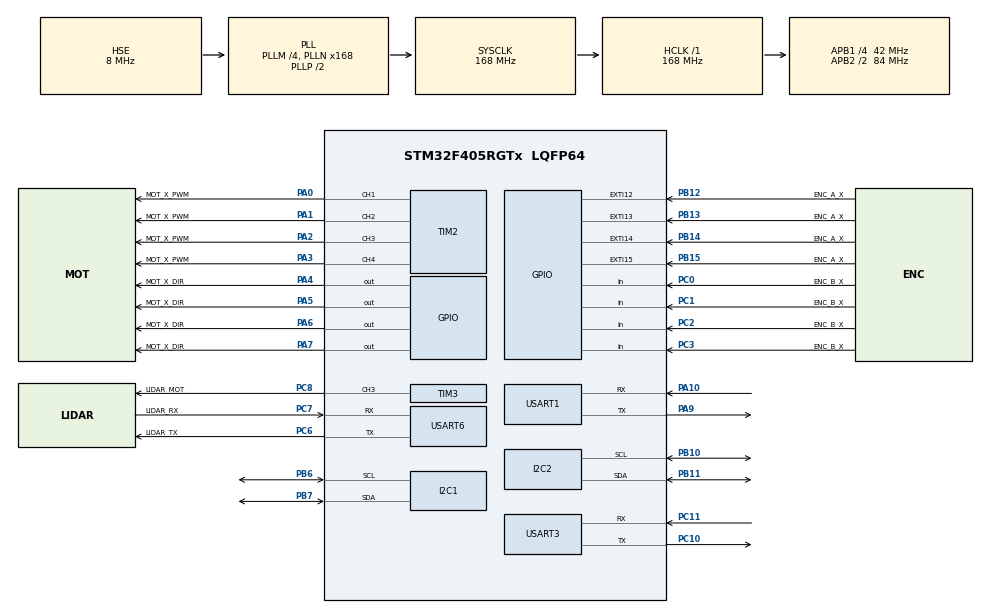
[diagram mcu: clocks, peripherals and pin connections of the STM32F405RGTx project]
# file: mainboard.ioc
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ADC1.Channel-2\#ChannelRegularConversion=ADC_CHANNEL_VBAT
ADC1.NbrOfConversion=1
ADC1.NbrOfConversionFlag=1
ADC1.Rank-2\#ChannelRegularConversion=1
ADC1.SamplingTime-2\#ChannelRegularConversion=ADC_SAMPLETIME_3CYCLES
ADC1.master=1
I2C1.I2C_Mode=I2C_Fast
I2C2.I2C_Mode=I2C_Fast
Mcu.Family=STM32F4
Mcu.Name=STM32F405RGTx
Mcu.Package=LQFP64
NVIC.EXTI15_10_IRQn=true\:0\:0\:false\:false\:true\:true\:true\:true
NVIC.PriorityGroup=NVIC_PRIORITYGROUP_4
PA0-WKUP.GPIO_Label=MOT_X_PWM
PA0-WKUP.Signal=S_TIM2_CH1_ETR
PA1.GPIO_Label=MOT_X_PWM
PA1.Signal=S_TIM2_CH2
PA10.Mode=Asynchronous
PA10.Signal=USART1_RX
PA13.Mode=Trace_Asynchronous_SW
PA13.Signal=SYS_JTMS-SWDIO
PA14.Mode=Trace_Asynchronous_SW
PA14.Signal=SYS_JTCK-SWCLK
PA2.GPIO_Label=MOT_X_PWM
PA2.Signal=S_TIM2_CH3
PA3.GPIO_Label=MOT_X_PWM
PA3.Signal=S_TIM2_CH4
PA4.GPIO_Label=MOT_X_DIR
PA4.Signal=GPIO_Output
PA5.GPIO_Label=MOT_X_DIR
PA5.Signal=GPIO_Output
PA6.GPIO_Label=MOT_X_DIR
PA6.Signal=GPIO_Output
PA7.GPIO_Label=MOT_X_DIR
PA7.Signal=GPIO_Output
PA9.Mode=Asynchronous
PA9.Signal=USART1_TX
PB10.Mode=I2C
PB10.Signal=I2C2_SCL
PB11.Mode=I2C
PB11.Signal=I2C2_SDA
PB12.GPIO_Label=ENC_A_X
PB12.Signal=GPXTI12
PB13.GPIO_Label=ENC_A_X
PB13.Signal=GPXTI13
PB14.GPIO_Label=ENC_A_X
PB14.Signal=GPXTI14
PB15.GPIO_Label=ENC_A_X
PB15.Signal=GPXTI15
PB3.Mode=Trace_Asynchronous_SW
PB3.Signal=SYS_JTDO-SWO
PB6.Mode=I2C
PB6.Signal=I2C1_SCL
PB7.Mode=I2C
PB7.Signal=I2C1_SDA
PC0.GPIO_Label=ENC_B_X
PC0.Signal=GPIO_Input
PC1.GPIO_Label=ENC_B_X
PC1.Signal=GPIO_Input
PC10.Mode=Asynchronous
PC10.Signal=USART3_TX
PC11.Mode=Asynchronous
PC11.Signal=USART3_RX
PC14-OSC32_IN.Mode=LSE-External-Oscillator
PC14-OSC32_IN.Signal=RCC_OSC32_IN
PC15-OSC32_OUT.Mode=LSE-External-Oscillator
PC15-OSC32_OUT.Signal=RCC_OSC32_OUT
PC2.GPIO_Label=ENC_B_X
PC2.Signal=GPIO_Input
PC3.GPIO_Label=ENC_B_X
PC3.Signal=GPIO_Input
PC6.GPIO_Label=LIDAR_TX
PC6.Mode=Asynchronous
PC6.Signal=USART6_TX
PC7.GPIO_Label=LIDAR_RX
PC7.Mode=Asynchronous
PC7.Signal=USART6_RX
PC8.GPIO_Label=LIDAR_MOT
PC8.Signal=S_TIM3_CH3
PH0-OSC_IN.Mode=HSE-External-Oscillator
PH0-OSC_IN.Signal=RCC_OSC_IN
PH1-OSC_OUT.Mode=HSE-External-Oscillator
PH1-OSC_OUT.Signal=RCC_OSC_OUT
ProjectManager.HeapSize=0x200
ProjectManager.StackSize=0x400
ProjectManager.TargetToolchain=STM32CubeIDE
RCC.48MHZClocksFreq_Value=84000000
RCC.AHBFreq_Value=168000000
RCC.APB1CLKDivider=RCC_HCLK_DIV4
RCC.APB1Freq_Value=42000000
RCC.APB1TimFreq_Value=84000000
RCC.APB2CLKDivider=RCC_HCLK_DIV2
RCC.APB2Freq_Value=84000000
RCC.APB2TimFreq_Value=168000000
RCC.CortexFreq_Value=168000000
RCC.HCLKFreq_Value=168000000
RCC.HSE_VALUE=8000000
RCC.HSI_VALUE=16000000
RCC.PLLM=4
RCC.PLLN=168
RCC.PLLSourceVirtual=RCC_PLLSOURCE_HSE
RCC.SYSCLKFreq_VALUE=168000000
RCC.SYSCLKSource=RCC_SYSCLKSOURCE_PLLCLK
RCC.VCOOutputFreq_Value=336000000
SH.S_TIM2_CH1_ETR.0=TIM2_CH1,PWM Generation1 CH1
SH.S_TIM2_CH2.0=TIM2_CH2,PWM Generation2 CH2
SH.S_TIM2_CH3.0=TIM2_CH3,PWM Generation3 CH3
SH.S_TIM2_CH4.0=TIM2_CH4,PWM Generation4 CH4
SH.S_TIM3_CH3.0=TIM3_CH3,PWM Generation3 CH3
TIM2.Channel-PWM\ Generation1\ CH1=TIM_CHANNEL_1
TIM2.Channel-PWM\ Generation2\ CH2=TIM_CHANNEL_2
TIM2.Channel-PWM\ Generation3\ CH3=TIM_CHANNEL_3
TIM2.Channel-PWM\ Generation4\ CH4=TIM_CHANNEL_4
TIM3.Channel-PWM\ Generation3\ CH3=TIM_CHANNEL_3
USART1.VirtualMode=VM_ASYNC
USART3.VirtualMode=VM_ASYNC
USART6.VirtualMode=VM_ASYNC
VP_ADC1_Vbat_Input.Mode=IN-Vbat
VP_TIM14_VS_ClockSourceINT.Mode=Enable_Timer
board=custom

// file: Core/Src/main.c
/* USER CODE BEGIN Header */
/**
  ******************************************************************************
  * @file           : main.c
  * @brief          : Main program body
  ******************************************************************************
  * @attention
  *
  * Copyright (c) 2024 STMicroelectronics.
  * All rights reserved.
  *
  * This software is licensed under terms that can be found in the LICENSE file
  * in the root directory of this software component.
  * If no LICENSE file comes with this software, it is provided AS-IS.
  *
  ******************************************************************************
  */
/* USER CODE END Header */
#include "main.h"

/* USER CODE BEGIN Includes */
#include <stdio.h>

int _read(int file, char *ptr, int len)
{
  (void)file;
  int DataIdx;

  for (DataIdx = 0; DataIdx < len; DataIdx++)
  {
    ITM_SendChar(*ptr++);
  }

  return len;
}
/* USER CODE END Includes */

ADC_HandleTypeDef hadc1;

I2C_HandleTypeDef hi2c1;
I2C_HandleTypeDef hi2c2;

TIM_HandleTypeDef htim2;
TIM_HandleTypeDef htim3;
TIM_HandleTypeDef htim14;

UART_HandleTypeDef huart1;
UART_HandleTypeDef huart3;
UART_HandleTypeDef huart6;

/* USER CODE BEGIN PV */
int a = 0;

//uint32_t tof1;
/* USER CODE END PV */

void SystemClock_Config(void);
static void MX_GPIO_Init(void);
static void MX_I2C2_Init(void);
static void MX_TIM2_Init(void);
static void MX_USART1_UART_Init(void);
static void MX_USART3_UART_Init(void);
static void MX_ADC1_Init(void);
static void MX_I2C1_Init(void);
static void MX_TIM14_Init(void);
static void MX_TIM3_Init(void);
static void MX_USART6_UART_Init(void);

int main(void)
{

  /* MCU Configuration--------------------------------------------------------*/

  /* Reset of all peripherals, Initializes the Flash interface and the Systick. */
  HAL_Init();

  /* Configure the system clock */
  SystemClock_Config();

  /* Initialize all configured peripherals */
  MX_GPIO_Init();
  MX_I2C2_Init();
  MX_TIM2_Init();
  MX_USART1_UART_Init();
  MX_USART3_UART_Init();
  MX_ADC1_Init();
  MX_I2C1_Init();
  MX_TIM14_Init();
  MX_TIM3_Init();
  MX_USART6_UART_Init();
  /* USER CODE BEGIN 2 */
  //VL53L3A2_RANGING_SENSOR_Init(tof1);
  //VL53L3A2_RANGING_SENSOR_Start(tof1, VL53L3A2_RANGING_SENSOR_);
  /* USER CODE END 2 */

  /* Infinite loop */
  /* USER CODE BEGIN WHILE */
  while (1)
  {
	  //VL53L3A2_RANGING_SENSOR_GetDistance(tof1, a);
	  HAL_GPIO_WritePin(GPIOB, GPIO_PIN_2, 1);
	  HAL_Delay(200);
	  a++;
	  //printf("aa");
	  HAL_GPIO_WritePin(GPIOB, GPIO_PIN_2, 0);
	  HAL_Delay(200);
	  a++;
	  //printf("bb");
    /* USER CODE END WHILE */

  }
}

void SystemClock_Config(void)
{
  RCC_OscInitTypeDef RCC_OscInitStruct = {0};
  RCC_ClkInitTypeDef RCC_ClkInitStruct = {0};

  /** Configure the main internal regulator output voltage
  */
  __HAL_RCC_PWR_CLK_ENABLE();
  __HAL_PWR_VOLTAGESCALING_CONFIG(PWR_REGULATOR_VOLTAGE_SCALE1);

  /** Initializes the RCC Oscillators according to the specified parameters
  * in the RCC_OscInitTypeDef structure.
  */
  RCC_OscInitStruct.OscillatorType = RCC_OSCILLATORTYPE_HSE;
  RCC_OscInitStruct.HSEState = RCC_HSE_ON;
  RCC_OscInitStruct.PLL.PLLState = RCC_PLL_ON;
  RCC_OscInitStruct.PLL.PLLSource = RCC_PLLSOURCE_HSE;
  RCC_OscInitStruct.PLL.PLLM = 4;
  RCC_OscInitStruct.PLL.PLLN = 168;
  RCC_OscInitStruct.PLL.PLLP = RCC_PLLP_DIV2;
  RCC_OscInitStruct.PLL.PLLQ = 4;
  if (HAL_RCC_OscConfig(&RCC_OscInitStruct) != HAL_OK)
  {
    Error_Handler();
  }

  /** Initializes the CPU, AHB and APB buses clocks
  */
  RCC_ClkInitStruct.ClockType = RCC_CLOCKTYPE_HCLK|RCC_CLOCKTYPE_SYSCLK
                              |RCC_CLOCKTYPE_PCLK1|RCC_CLOCKTYPE_PCLK2;
  RCC_ClkInitStruct.SYSCLKSource = RCC_SYSCLKSOURCE_PLLCLK;
  RCC_ClkInitStruct.AHBCLKDivider = RCC_SYSCLK_DIV1;
  RCC_ClkInitStruct.APB1CLKDivider = RCC_HCLK_DIV4;
  RCC_ClkInitStruct.APB2CLKDivider = RCC_HCLK_DIV2;

  if (HAL_RCC_ClockConfig(&RCC_ClkInitStruct, FLASH_LATENCY_5) != HAL_OK)
  {
    Error_Handler();
  }
}

static void MX_ADC1_Init(void)
{

  ADC_ChannelConfTypeDef sConfig = {0};

  /** Configure the global features of the ADC (Clock, Resolution, Data Alignment and number of conversion)
  */
  hadc1.Instance = ADC1;
  hadc1.Init.ClockPrescaler = ADC_CLOCK_SYNC_PCLK_DIV4;
  hadc1.Init.Resolution = ADC_RESOLUTION_12B;
  hadc1.Init.ScanConvMode = DISABLE;
  hadc1.Init.ContinuousConvMode = DISABLE;
  hadc1.Init.DiscontinuousConvMode = DISABLE;
  hadc1.Init.ExternalTrigConvEdge = ADC_EXTERNALTRIGCONVEDGE_NONE;
  hadc1.Init.ExternalTrigConv = ADC_SOFTWARE_START;
  hadc1.Init.DataAlign = ADC_DATAALIGN_RIGHT;
  hadc1.Init.NbrOfConversion = 1;
  hadc1.Init.DMAContinuousRequests = DISABLE;
  hadc1.Init.EOCSelection = ADC_EOC_SINGLE_CONV;
  if (HAL_ADC_Init(&hadc1) != HAL_OK)
  {
    Error_Handler();
  }

  /** Configure for the selected ADC regular channel its corresponding rank in the sequencer and its sample time.
  */
  sConfig.Channel = ADC_CHANNEL_VBAT;
  sConfig.Rank = 1;
  sConfig.SamplingTime = ADC_SAMPLETIME_3CYCLES;
  if (HAL_ADC_ConfigChannel(&hadc1, &sConfig) != HAL_OK)
  {
    Error_Handler();
  }

}

static void MX_I2C1_Init(void)
{

  hi2c1.Instance = I2C1;
  hi2c1.Init.ClockSpeed = 400000;
  hi2c1.Init.DutyCycle = I2C_DUTYCYCLE_2;
  hi2c1.Init.OwnAddress1 = 0;
  hi2c1.Init.AddressingMode = I2C_ADDRESSINGMODE_7BIT;
  hi2c1.Init.DualAddressMode = I2C_DUALADDRESS_DISABLE;
  hi2c1.Init.OwnAddress2 = 0;
  hi2c1.Init.GeneralCallMode = I2C_GENERALCALL_DISABLE;
  hi2c1.Init.NoStretchMode = I2C_NOSTRETCH_DISABLE;
  if (HAL_I2C_Init(&hi2c1) != HAL_OK)
  {
    Error_Handler();
  }

}

static void MX_I2C2_Init(void)
{

  hi2c2.Instance = I2C2;
  hi2c2.Init.ClockSpeed = 400000;
  hi2c2.Init.DutyCycle = I2C_DUTYCYCLE_2;
  hi2c2.Init.OwnAddress1 = 0;
  hi2c2.Init.AddressingMode = I2C_ADDRESSINGMODE_7BIT;
  hi2c2.Init.DualAddressMode = I2C_DUALADDRESS_DISABLE;
  hi2c2.Init.OwnAddress2 = 0;
  hi2c2.Init.GeneralCallMode = I2C_GENERALCALL_DISABLE;
  hi2c2.Init.NoStretchMode = I2C_NOSTRETCH_DISABLE;
  if (HAL_I2C_Init(&hi2c2) != HAL_OK)
  {
    Error_Handler();
  }

}

static void MX_TIM2_Init(void)
{

  TIM_MasterConfigTypeDef sMasterConfig = {0};
  TIM_OC_InitTypeDef sConfigOC = {0};

  htim2.Instance = TIM2;
  htim2.Init.Prescaler = 0;
  htim2.Init.CounterMode = TIM_COUNTERMODE_UP;
  htim2.Init.Period = 4294967295;
  htim2.Init.ClockDivision = TIM_CLOCKDIVISION_DIV1;
  htim2.Init.AutoReloadPreload = TIM_AUTORELOAD_PRELOAD_DISABLE;
  if (HAL_TIM_PWM_Init(&htim2) != HAL_OK)
  {
    Error_Handler();
  }
  sMasterConfig.MasterOutputTrigger = TIM_TRGO_RESET;
  sMasterConfig.MasterSlaveMode = TIM_MASTERSLAVEMODE_DISABLE;
  if (HAL_TIMEx_MasterConfigSynchronization(&htim2, &sMasterConfig) != HAL_OK)
  {
    Error_Handler();
  }
  sConfigOC.OCMode = TIM_OCMODE_PWM1;
  sConfigOC.Pulse = 0;
  sConfigOC.OCPolarity = TIM_OCPOLARITY_HIGH;
  sConfigOC.OCFastMode = TIM_OCFAST_DISABLE;
  if (HAL_TIM_PWM_ConfigChannel(&htim2, &sConfigOC, TIM_CHANNEL_1) != HAL_OK)
  {
    Error_Handler();
  }
  if (HAL_TIM_PWM_ConfigChannel(&htim2, &sConfigOC, TIM_CHANNEL_2) != HAL_OK)
  {
    Error_Handler();
  }
  if (HAL_TIM_PWM_ConfigChannel(&htim2, &sConfigOC, TIM_CHANNEL_3) != HAL_OK)
  {
    Error_Handler();
  }
  if (HAL_TIM_PWM_ConfigChannel(&htim2, &sConfigOC, TIM_CHANNEL_4) != HAL_OK)
  {
    Error_Handler();
  }
  HAL_TIM_MspPostInit(&htim2);

}

static void MX_TIM3_Init(void)
{

  TIM_MasterConfigTypeDef sMasterConfig = {0};
  TIM_OC_InitTypeDef sConfigOC = {0};

  htim3.Instance = TIM3;
  htim3.Init.Prescaler = 0;
  htim3.Init.CounterMode = TIM_COUNTERMODE_UP;
  htim3.Init.Period = 65535;
  htim3.Init.ClockDivision = TIM_CLOCKDIVISION_DIV1;
  htim3.Init.AutoReloadPreload = TIM_AUTORELOAD_PRELOAD_DISABLE;
  if (HAL_TIM_PWM_Init(&htim3) != HAL_OK)
  {
    Error_Handler();
  }
  sMasterConfig.MasterOutputTrigger = TIM_TRGO_RESET;
  sMasterConfig.MasterSlaveMode = TIM_MASTERSLAVEMODE_DISABLE;
  if (HAL_TIMEx_MasterConfigSynchronization(&htim3, &sMasterConfig) != HAL_OK)
  {
    Error_Handler();
  }
  sConfigOC.OCMode = TIM_OCMODE_PWM1;
  sConfigOC.Pulse = 0;
  sConfigOC.OCPolarity = TIM_OCPOLARITY_HIGH;
  sConfigOC.OCFastMode = TIM_OCFAST_DISABLE;
  if (HAL_TIM_PWM_ConfigChannel(&htim3, &sConfigOC, TIM_CHANNEL_3) != HAL_OK)
  {
    Error_Handler();
  }
  HAL_TIM_MspPostInit(&htim3);

}

static void MX_TIM14_Init(void)
{

  htim14.Instance = TIM14;
  htim14.Init.Prescaler = 0;
  htim14.Init.CounterMode = TIM_COUNTERMODE_UP;
  htim14.Init.Period = 65535;
  htim14.Init.ClockDivision = TIM_CLOCKDIVISION_DIV1;
  htim14.Init.AutoReloadPreload = TIM_AUTORELOAD_PRELOAD_DISABLE;
  if (HAL_TIM_Base_Init(&htim14) != HAL_OK)
  {
    Error_Handler();
  }

}

static void MX_USART1_UART_Init(void)
{

  huart1.Instance = USART1;
  huart1.Init.BaudRate = 115200;
  huart1.Init.WordLength = UART_WORDLENGTH_8B;
  huart1.Init.StopBits = UART_STOPBITS_1;
  huart1.Init.Parity = UART_PARITY_NONE;
  huart1.Init.Mode = UART_MODE_TX_RX;
  huart1.Init.HwFlowCtl = UART_HWCONTROL_NONE;
  huart1.Init.OverSampling = UART_OVERSAMPLING_16;
  if (HAL_UART_Init(&huart1) != HAL_OK)
  {
    Error_Handler();
  }

}

static void MX_USART3_UART_Init(void)
{

  huart3.Instance = USART3;
  huart3.Init.BaudRate = 115200;
  huart3.Init.WordLength = UART_WORDLENGTH_8B;
  huart3.Init.StopBits = UART_STOPBITS_1;
  huart3.Init.Parity = UART_PARITY_NONE;
  huart3.Init.Mode = UART_MODE_TX_RX;
  huart3.Init.HwFlowCtl = UART_HWCONTROL_NONE;
  huart3.Init.OverSampling = UART_OVERSAMPLING_16;
  if (HAL_UART_Init(&huart3) != HAL_OK)
  {
    Error_Handler();
  }

}

static void MX_USART6_UART_Init(void)
{

  huart6.Instance = USART6;
  huart6.Init.BaudRate = 115200;
  huart6.Init.WordLength = UART_WORDLENGTH_8B;
  huart6.Init.StopBits = UART_STOPBITS_1;
  huart6.Init.Parity = UART_PARITY_NONE;
  huart6.Init.Mode = UART_MODE_TX_RX;
  huart6.Init.HwFlowCtl = UART_HWCONTROL_NONE;
  huart6.Init.OverSampling = UART_OVERSAMPLING_16;
  if (HAL_UART_Init(&huart6) != HAL_OK)
  {
    Error_Handler();
  }

}

static void MX_GPIO_Init(void)
{
  GPIO_InitTypeDef GPIO_InitStruct = {0};

  /* GPIO Ports Clock Enable */
  __HAL_RCC_GPIOC_CLK_ENABLE();
  __HAL_RCC_GPIOH_CLK_ENABLE();
  __HAL_RCC_GPIOA_CLK_ENABLE();
  __HAL_RCC_GPIOB_CLK_ENABLE();

  /*Configure GPIO pin Output Level */
  HAL_GPIO_WritePin(GPIOA, MOT_X_DIR_Pin|MOT_X_DIRA5_Pin|MOT_X_DIRA6_Pin|MOT_X_DIRA7_Pin, GPIO_PIN_RESET);

  /*Configure GPIO pins : ENC_B_X_Pin ENC_B_XC1_Pin ENC_B_XC2_Pin ENC_B_XC3_Pin */
  GPIO_InitStruct.Pin = ENC_B_X_Pin|ENC_B_XC1_Pin|ENC_B_XC2_Pin|ENC_B_XC3_Pin;
  GPIO_InitStruct.Mode = GPIO_MODE_INPUT;
  GPIO_InitStruct.Pull = GPIO_NOPULL;
  HAL_GPIO_Init(GPIOC, &GPIO_InitStruct);

  /*Configure GPIO pins : MOT_X_DIR_Pin MOT_X_DIRA5_Pin MOT_X_DIRA6_Pin MOT_X_DIRA7_Pin */
  GPIO_InitStruct.Pin = MOT_X_DIR_Pin|MOT_X_DIRA5_Pin|MOT_X_DIRA6_Pin|MOT_X_DIRA7_Pin;
  GPIO_InitStruct.Mode = GPIO_MODE_OUTPUT_PP;
  GPIO_InitStruct.Pull = GPIO_NOPULL;
  GPIO_InitStruct.Speed = GPIO_SPEED_FREQ_LOW;
  HAL_GPIO_Init(GPIOA, &GPIO_InitStruct);

  /*Configure GPIO pins : ENC_A_X_Pin ENC_A_XB13_Pin ENC_A_XB14_Pin ENC_A_XB15_Pin */
  GPIO_InitStruct.Pin = ENC_A_X_Pin|ENC_A_XB13_Pin|ENC_A_XB14_Pin|ENC_A_XB15_Pin;
  GPIO_InitStruct.Mode = GPIO_MODE_IT_RISING;
  GPIO_InitStruct.Pull = GPIO_NOPULL;
  HAL_GPIO_Init(GPIOB, &GPIO_InitStruct);

  /* EXTI interrupt init*/
  HAL_NVIC_SetPriority(EXTI15_10_IRQn, 0, 0);
  HAL_NVIC_EnableIRQ(EXTI15_10_IRQn);

}

void Error_Handler(void)
{
  __disable_irq();
  while (1)
  {
  }
}
